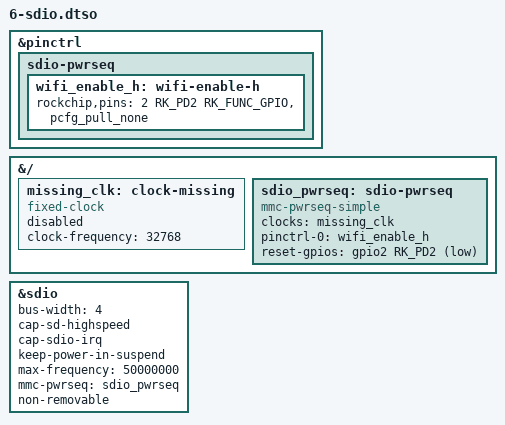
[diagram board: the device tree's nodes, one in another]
// SPDX-License-Identifier: (GPL-2.0+ OR MIT)
/dts-v1/; /plugin/;
#include <dt-bindings/gpio/gpio.h>
#include <dt-bindings/pinctrl/rockchip.h>
#include <dt-bindings/interrupt-controller/irq.h>
&pinctrl { sdio-pwrseq { wifi_enable_h: wifi-enable-h { rockchip,pins = <2 RK_PD2 RK_FUNC_GPIO &pcfg_pull_none>; }; }; };
&{/} { missing_clk: clock-missing { compatible = "fixed-clock"; #clock-cells = <0>; clock-frequency = <32768>; status = "disabled"; };
  sdio_pwrseq: sdio-pwrseq { compatible = "mmc-pwrseq-simple"; clocks = <&missing_clk>; clock-names = "ext_clock"; pinctrl-names = "default"; pinctrl-0 = <&wifi_enable_h>; reset-gpios = <&gpio2 RK_PD2 GPIO_ACTIVE_LOW>; }; };
&sdio { #address-cells = <1>; #size-cells = <0>; bus-width = <4>; cap-sd-highspeed; cap-sdio-irq; keep-power-in-suspend; max-frequency = <50000000>; mmc-pwrseq = <&sdio_pwrseq>; non-removable; status = "okay"; };
